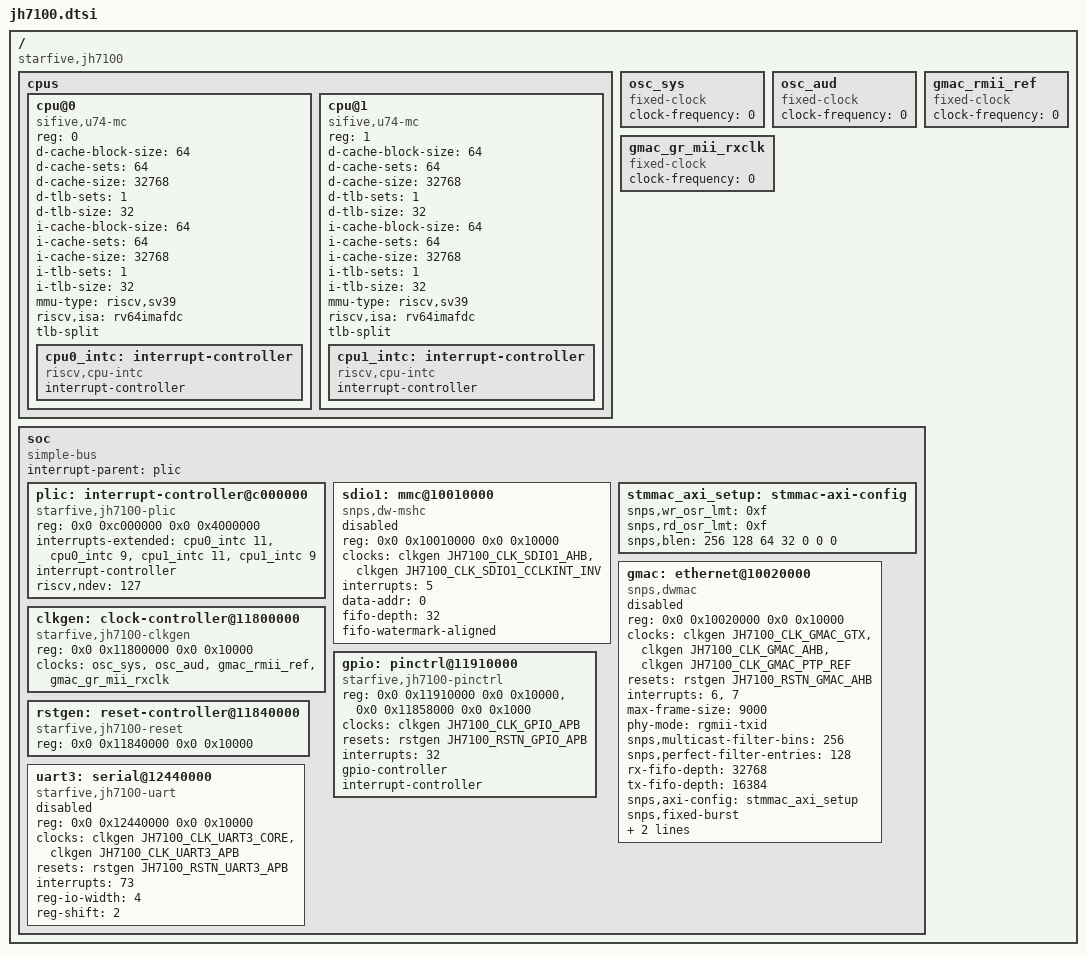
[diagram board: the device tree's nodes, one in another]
// SPDX-License-Identifier: GPL-2.0 OR MIT
/*
 * Copyright (C) 2021 StarFive Technology Co., Ltd.
 * Copyright (C) 2021 Emil Renner Berthing <kernel@esmil.dk>
 */

/dts-v1/;
#include "starfive_vic7100_clk.dtsi"
#include <dt-bindings/clock/starfive-jh7100.h>
#include <dt-bindings/clock/starfive-jh7100-audio.h>
#include <dt-bindings/clock/starfive-jh7100-isp.h>
#include <dt-bindings/reset/starfive-jh7100.h>
#include <dt-bindings/reset/starfive-jh7100-audio.h>
#include <dt-bindings/reset/starfive-jh7100-isp.h>
#include <dt-bindings/starfive_fb.h>

/ {
	compatible = "starfive,jh7100";
	#address-cells = <2>;
	#size-cells = <2>;

	cpus {
		#address-cells = <1>;
		#size-cells = <0>;

		cpu@0 {
			compatible = "sifive,u74-mc", "riscv";
			reg = <0>;
			d-cache-block-size = <64>;
			d-cache-sets = <64>;
			d-cache-size = <32768>;
			d-tlb-sets = <1>;
			d-tlb-size = <32>;
			device_type = "cpu";
			i-cache-block-size = <64>;
			i-cache-sets = <64>;
			i-cache-size = <32768>;
			i-tlb-sets = <1>;
			i-tlb-size = <32>;
			mmu-type = "riscv,sv39";
			riscv,isa = "rv64imafdc";
			tlb-split;

			cpu0_intc: interrupt-controller {
				compatible = "riscv,cpu-intc";
				interrupt-controller;
				#interrupt-cells = <1>;
			};
		};

		cpu@1 {
			compatible = "sifive,u74-mc", "riscv";
			reg = <1>;
			d-cache-block-size = <64>;
			d-cache-sets = <64>;
			d-cache-size = <32768>;
			d-tlb-sets = <1>;
			d-tlb-size = <32>;
			device_type = "cpu";
			i-cache-block-size = <64>;
			i-cache-sets = <64>;
			i-cache-size = <32768>;
			i-tlb-sets = <1>;
			i-tlb-size = <32>;
			mmu-type = "riscv,sv39";
			riscv,isa = "rv64imafdc";
			tlb-split;

			cpu1_intc: interrupt-controller {
				compatible = "riscv,cpu-intc";
				interrupt-controller;
				#interrupt-cells = <1>;
			};
		};
	};

    // sys clock
	osc_sys: osc_sys {
		compatible = "fixed-clock";
		#clock-cells = <0>;
		/* This value must be overridden by the board */
		clock-frequency = <0>;
	};

	osc_aud: osc_aud {
		compatible = "fixed-clock";
		#clock-cells = <0>;
		/* This value must be overridden by the board */
		clock-frequency = <0>;
	};

    gmac_rmii_ref: gmac_rmii_ref {
		compatible = "fixed-clock";
		#clock-cells = <0>;
		/* Should be overridden by the board when needed */
		clock-frequency = <0>;
	};

	gmac_gr_mii_rxclk: gmac_gr_mii_rxclk {
		compatible = "fixed-clock";
		#clock-cells = <0>;
		/* Should be overridden by the board when needed */
		clock-frequency = <0>;
	};

	soc {
		compatible = "simple-bus";
		interrupt-parent = <&plic>;
		#address-cells = <2>;
		#size-cells = <2>;
		ranges;

		plic: interrupt-controller@c000000 {
			compatible = "starfive,jh7100-plic", "sifive,plic-1.0.0";
			reg = <0x0 0xc000000 0x0 0x4000000>;
			interrupts-extended = <&cpu0_intc 11>, <&cpu0_intc 9>,
					      <&cpu1_intc 11>, <&cpu1_intc 9>;
			interrupt-controller;
			#address-cells = <0>;
			#interrupt-cells = <1>;
			riscv,ndev = <127>;
		};

        sdio1: mmc@10010000 {
			compatible = "snps,dw-mshc";
			reg = <0x0 0x10010000 0x0 0x10000>;
			clocks = <&clkgen JH7100_CLK_SDIO1_AHB>,
				 <&clkgen JH7100_CLK_SDIO1_CCLKINT_INV>;
			clock-names = "biu", "ciu";
			interrupts = <5>;
			data-addr = <0>;
			fifo-depth = <32>;
			fifo-watermark-aligned;
			status = "disabled";
		};

        /* gmac device configuration */
		stmmac_axi_setup: stmmac-axi-config {
			snps,wr_osr_lmt = <0xf>;
			snps,rd_osr_lmt = <0xf>;
			snps,blen = <256 128 64 32 0 0 0>;
		};

		gmac: ethernet@10020000 {
			compatible = "snps,dwmac";
			reg = <0x0 0x10020000 0x0 0x10000>;
			clocks = <&clkgen JH7100_CLK_GMAC_GTX>,
				 <&clkgen JH7100_CLK_GMAC_AHB>,
				 <&clkgen JH7100_CLK_GMAC_PTP_REF>;
			clock-names = "stmmaceth", "pclk", "ptp_ref";
			resets = <&rstgen JH7100_RSTN_GMAC_AHB>;
			reset-names = "ahb";
			interrupts = <6>, <7>;
			interrupt-names = "macirq", "eth_wake_irq";
			max-frame-size = <9000>;
			phy-mode = "rgmii-txid";
			snps,multicast-filter-bins = <256>;
			snps,perfect-filter-entries = <128>;
			rx-fifo-depth = <32768>;
			tx-fifo-depth = <16384>;
			snps,axi-config = <&stmmac_axi_setup>;
			snps,fixed-burst;
			/*snps,force_sf_dma_mode;*/
			snps,force_thresh_dma_mode;
			snps,no-pbl-x8 = <1>;
			status = "disabled";
		};

		clkgen: clock-controller@11800000 {
			compatible = "starfive,jh7100-clkgen";
			reg = <0x0 0x11800000 0x0 0x10000>;
			clocks = <&osc_sys>, <&osc_aud>, <&gmac_rmii_ref>, <&gmac_gr_mii_rxclk>;
			clock-names = "osc_sys", "osc_aud", "gmac_rmii_ref", "gmac_gr_mii_rxclk";
			#clock-cells = <1>;
		};

		rstgen: reset-controller@11840000 {
			compatible = "starfive,jh7100-reset";
			reg = <0x0 0x11840000 0x0 0x10000>;
			#reset-cells = <1>;
		};

		gpio: pinctrl@11910000 {
			compatible = "starfive,jh7100-pinctrl";
			reg = <0x0 0x11910000 0x0 0x10000>,
			      <0x0 0x11858000 0x0 0x1000>;
			reg-names = "gpio", "padctl";
			clocks = <&clkgen JH7100_CLK_GPIO_APB>;
			resets = <&rstgen JH7100_RSTN_GPIO_APB>;
			interrupts = <32>;
			gpio-controller;
			#gpio-cells = <2>;
			interrupt-controller;
			#interrupt-cells = <2>;
		};

		uart3: serial@12440000 {
			compatible = "starfive,jh7100-uart", "snps,dw-apb-uart";
			reg = <0x0 0x12440000 0x0 0x10000>;
			clocks = <&clkgen JH7100_CLK_UART3_CORE>,
				 <&clkgen JH7100_CLK_UART3_APB>;
			clock-names = "baudclk", "apb_pclk";
			resets = <&rstgen JH7100_RSTN_UART3_APB>;
			interrupts = <73>;
			reg-io-width = <4>;
			reg-shift = <2>;
			status = "disabled";
		};
	};
};
